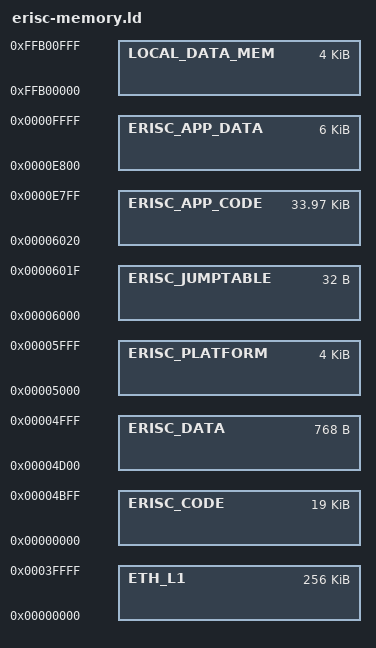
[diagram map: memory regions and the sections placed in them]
MEMORY
{
    LOCAL_DATA_MEM : ORIGIN = 0xFFB00000, LENGTH = 4K
    ETH_L1 : ORIGIN = 0x00000000, LENGTH = 256K
    ERISC_CODE : ORIGIN = 0x00000000, LENGTH = 19K
    ERISC_DATA : ORIGIN = 0x00004D00, LENGTH = 768
    ERISC_PLATFORM : ORIGIN = 0x00005000, LENGTH = 4K
    ERISC_JUMPTABLE : ORIGIN = 0x00006000, LENGTH = 32
    ERISC_APP_CODE : ORIGIN = 0x00006020, LENGTH = 34K - 32
    ERISC_APP_DATA : ORIGIN = 0x0000E800, LENGTH = 6K
}
